# STM32C542xx register map
File version: 1.0
Registers are 32-bit, read-write, reset 0x0 unless marked. A register's access mark holds for its fields unless they carry their own. Offsets are from the block's base; [hi:lo] are bit positions.

## ADC12_COMMON
Base 0x42028300
0x00 CSR ro — ADC common status register
0x08 CCR — ADC common control register
0x0C CDR ro — ADC common regular data register for dual mode
0x10 CDR2 ro — ADC common regular data register for dual mode

## DAC1 — Digital to Analog Converter
Base 0x42028400
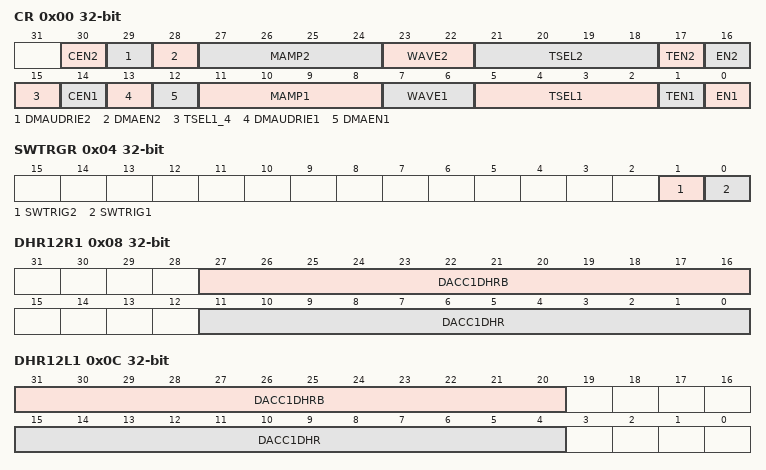
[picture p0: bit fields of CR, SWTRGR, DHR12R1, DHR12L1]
0x00 CR — DAC control register
  [30] CEN2 — DAC channel2 calibration enable
  [29] DMAUDRIE2
  [28] DMAEN2 — DAC channel2 DMA enable
  [27:24] MAMP2 — DAC channel2 mask/amplitude selector
  [23:22] WAVE2
  [21:18] TSEL2 — DAC channel2 trigger selection
  [17] TEN2 — DAC channel2 trigger enable
  [16] EN2 — DAC channel2 enable
  [15] TSEL1_4 — DAC channel1 trigger selection
  [14] CEN1 — DAC channel1 calibration enable
  [13] DMAUDRIE1
  [12] DMAEN1 — DAC channel1 DMA enable
  [11:8] MAMP1 — DAC channel1 mask/amplitude selector
  [7:6] WAVE1
  [5:2] TSEL1 — DAC channel1 trigger selection
  [1] TEN1 — DAC channel1 trigger enable
  [0] EN1 — DAC channel1 enable
0x04 SWTRGR — DAC software trigger register
  [1] SWTRIG2 — DAC channel2 software trigger
  [0] SWTRIG1
0x08 DHR12R1 — DAC channel1 12-bit right-aligned data holding register
  [27:16] DACC1DHRB, [11:0] DACC1DHR
0x0C DHR12L1 — DAC channel1 12-bit left aligned data holding register
  [31:20] DACC1DHRB
  [15:4] DACC1DHR — DAC channel1 12-bit left-aligned data
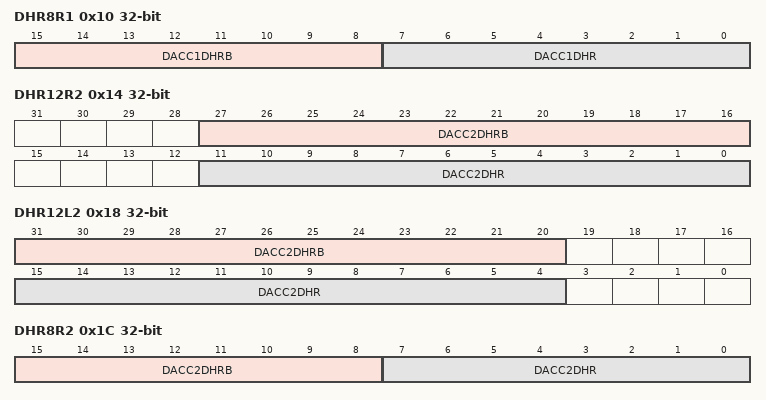
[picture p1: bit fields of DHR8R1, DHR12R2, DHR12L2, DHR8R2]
0x10 DHR8R1 — DAC channel1 8-bit right aligned data holding register
  [15:8] DACC1DHRB — DAC channel1 8-bit right-aligned data
  [7:0] DACC1DHR — DAC channel1 8-bit right-aligned data
0x14 DHR12R2 — DAC channel2 12-bit right aligned data holding register
  [27:16] DACC2DHRB, [11:0] DACC2DHR
0x18 DHR12L2 — DAC channel2 12-bit left aligned data holding register
  [31:20] DACC2DHRB, [15:4] DACC2DHR
0x1C DHR8R2 — DAC channel2 8-bit right-aligned data holding register
  [15:8] DACC2DHRB — DAC channel2 8-bit right-aligned data
  [7:0] DACC2DHR — DAC channel2 8-bit right-aligned data
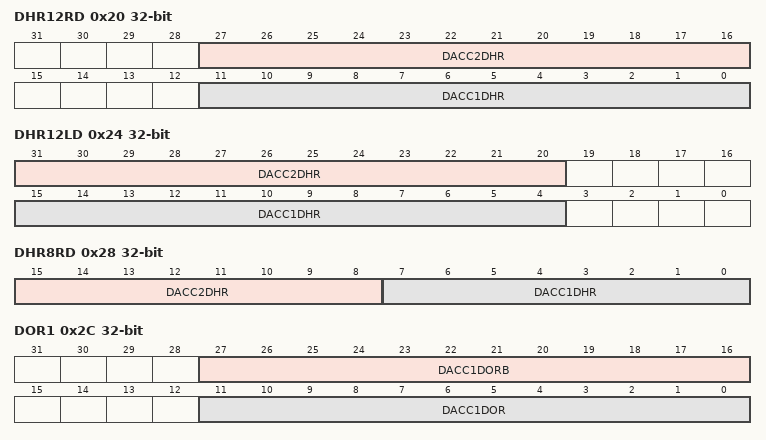
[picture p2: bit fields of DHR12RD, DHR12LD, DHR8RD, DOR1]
0x20 DHR12RD — Dual DAC 12-bit right-aligned data holding register
  [27:16] DACC2DHR, [11:0] DACC1DHR
0x24 DHR12LD — Dual DAC 12-bit left aligned data holding register
  [31:20] DACC2DHR — DAC channel2 12-bit left-aligned data
  [15:4] DACC1DHR — DAC channel1 12-bit left-aligned data
0x28 DHR8RD — Dual DAC 8-bit right aligned data holding register
  [15:8] DACC2DHR — DAC channel2 8-bit right-aligned data
  [7:0] DACC1DHR — DAC channel1 8-bit right-aligned data
0x2C DOR1 ro — DAC channel1 data output register
  [27:16] DACC1DORB — DAC channel1 data output
  [11:0] DACC1DOR — DAC channel1 data output
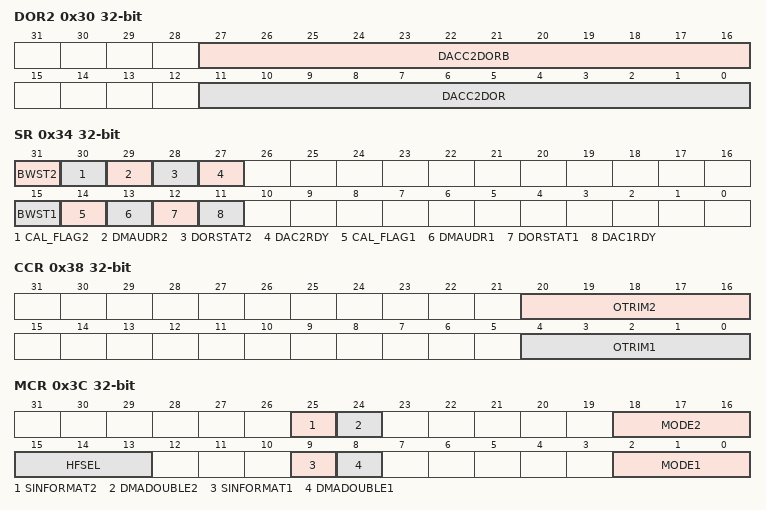
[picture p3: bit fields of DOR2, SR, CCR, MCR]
0x30 DOR2 ro — DAC channel2 data output register
  [27:16] DACC2DORB — DAC channel2 data output
  [11:0] DACC2DOR — DAC channel2 data output
0x34 SR — DAC status register
  [31] BWST2
  [30] CAL_FLAG2
  [29] DMAUDR2 — DAC channel2 DMA underrun flag
  [28] DORSTAT2
  [27] DAC2RDY — DAC channel2 ready status bit
  [15] BWST1
  [14] CAL_FLAG1
  [13] DMAUDR1 — DAC channel1 DMA underrun flag
  [12] DORSTAT1
  [11] DAC1RDY — DAC channel1 ready status bit
0x38 CCR — DAC calibration control register
  [20:16] OTRIM2 — DAC channel2 offset trimming value
  [4:0] OTRIM1 — DAC channel1 offset trimming value
0x3C MCR — DAC mode control register
  [25] SINFORMAT2 — Enable signed format for DAC channel2
  [24] DMADOUBLE2 — DAC channel2 DMA double data mode
  [18:16] MODE2 — DAC channel2 mode
  [15:13] HFSEL
  [9] SINFORMAT1 — Enable signed format for DAC channel1
  [8] DMADOUBLE1 — DAC channel1 DMA double data mode
  [2:0] MODE1 — DAC channel1 mode
0x40 SHSR1 — DAC channel1 sample and hold sample time register
  [9:0] TSAMPLE1
0x44 SHSR2 — DAC channel2 sample and hold sample time register
  [9:0] TSAMPLE2
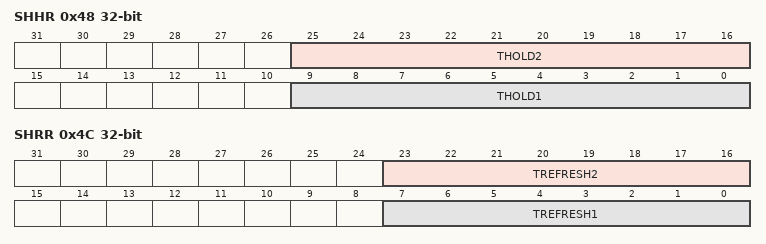
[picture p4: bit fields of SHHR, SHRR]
0x48 SHHR — DAC sample and hold time register
  [25:16] THOLD2, [9:0] THOLD1
0x4C SHRR — DAC sample and hold refresh time register
  [23:16] TREFRESH2, [7:0] TREFRESH1
